# STM32MP25_CM0P register map
File version: 1.0
CPU: CM0PLUS r0p1, little endian, MPU, no FPU, vendor SysTick, 8 interrupt priority bits
Registers are 32-bit, read-write, reset 0x0 unless marked. A register's access mark holds for its fields unless they carry their own. Offsets are from the block's base; [hi:lo] are bit positions.

## IWDG5 — IWDG register block
Base 0x46090000
0x00 IWDG_KR wo — IWDG key register
  [15:0] KEY — Key value (write only, read 0x0000) These bits must be written by software at regular intervals with the key value 0xAAAA, otherwise the watchdog generates a reset when the counter reaches 0. Writing the key value 0x5555 to enable access to the IWDG_PR, IWDG_RLR and IWDG_WINR registers (see ) Writing the key value 0xCCCC starts the watchdog (except if the hardware watchdog option is selected)
0x04 IWDG_PR reset 0xF — IWDG prescaler register
  [3:0] PR — Prescaler divider These bits are write access protected see . They are written by software to select the prescaler divider feeding the counter clock. PVU bit of the must be reset in order to be able to change the prescaler divider. others: divider / 1024 Note: Reading this register returns the prescaler value from the VDD voltage domain. This value may not be up to date/valid if a write operation to this register is ongoing. For this reason the value read from this register is valid only when the PVU bit in the status register (IWDG_SR) is reset.
    0=divider / 4; 1=divider / 8; 2=divider / 16; 3=divider / 32; 4=divider / 64; 5=divider / 128; 6=divider / 256; 7=divider / 512
0x08 IWDG_RLR reset 0xFFF — IWDG reload register
  [11:0] RL — Watchdog counter reload value These bits are write access protected see . They are written by software to define the value to be loaded in the watchdog counter each time the value 0xAAAA is written in the . The watchdog counter counts down from this value. The timeout period is a function of this value and the prescaler.clock. It is not recommended to set RL[11:0] to a value lower than 2. The RVU bit in the must be reset to be able to change the reload value. Note: Reading this register returns the reload value from the VDD voltage domain. This value may not be up to date/valid if a write operation to this register is ongoing on it. For this reason the value read from this register is valid only when the RVU bit in the status register (IWDG_SR) is reset.
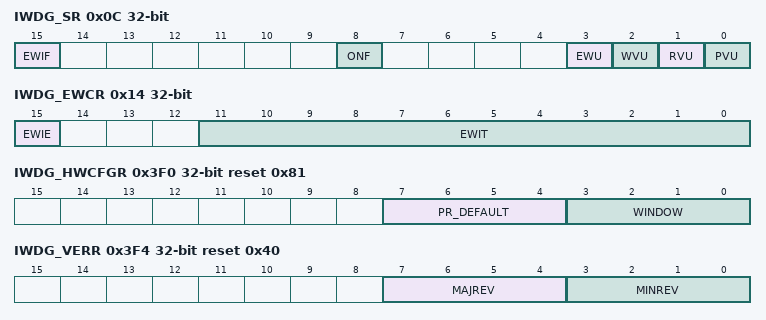
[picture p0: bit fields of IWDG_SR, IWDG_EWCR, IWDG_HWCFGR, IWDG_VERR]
0x0C IWDG_SR ro — IWDG status register
  [15] EWIF — Watchdog Early interrupt flag This bit is set to 1 by hardware in order to indicate that an early interrupt is pending. This bit must be cleared by the software by writing the bit EWIC of (IWDG_ICR) to 1 .
  [8] ONF — Watchdog enable status bit Set to 1 by hardware as soon as the IWDG is started, remains to 1 until the IWDG is reset.
    0=The IWDG is not activated; 1=The IWDG is activated and needs to be refreshed regularly by the application
  [3] EWU — Watchdog interrupt comparator value update This bit is set by hardware to indicate that an update of the interrupt comparator value (EWIT[11:0]) or an update of the EWIE is ongoing. It is reset by hardware when the update operation is completed in the VDD voltage domain (takes up to three periods of the IWDG kernel clock iwdg_ker_ck). The EWIT[11:0] and EWIE fields can be updated only when EWU bit is reset.
  [2] WVU — Watchdog counter window value update This bit is set by hardware to indicate that an update of the window value is ongoing. It is reset by hardware when the reload value update operation is completed in the VDD voltage domain (takes up to 3 periods of the IWDG kernel clock iwdg_ker_ck). The window value can be updated only when WVU bit is reset. This bit is generated only if generic 'window'= 1
  [1] RVU — Watchdog counter reload value update This bit is set by hardware to indicate that an update of the reload value is ongoing. It is reset by hardware when the reload value update operation is completed in the VDD voltage domain (takes up to 3 periods of the IWDG kernel clock iwdg_ker_ck). The reload value can be updated only when RVU bit is reset.
  [0] PVU — Watchdog prescaler value update This bit is set by hardware to indicate that an update of the prescaler value is ongoing. It is reset by hardware when the prescaler update operation is completed in the VDD voltage domain (takes up to 3 periods of the IWDG kernel clock iwdg_ker_ck). The prescaler value can be updated only when PVU bit is reset.
0x10 IWDG_WINR reset 0xFFF — IWDG window register
  [11:0] WIN — Watchdog counter window value These bits are write access protected, see , they contain the high limit of the window value to be compared with the downcounter. To prevent a reset, the IWDCNT downcounter must be reloaded when its value is lower than WIN[11:0]+1 and greater than 1. The WVU bit in the must be reset to be able to change the reload value. Note: Reading this register returns the reload value from the VDD voltage domain. This value may not be valid if a write operation to this register is ongoing. For this reason the value read from this register is valid only when the WVU bit in the (IWDG_SR) is reset.
0x14 IWDG_EWCR — IWDG early wakeup interrupt register
  [15] EWIE — Watchdog early interrupt enable Set and reset by software. The EWU bit in the must be reset to be able to change the value of this bit.
    0=The early interrupt interface is disabled; 1=The early interrupt interface is enabled
  [11:0] EWIT — Watchdog counter window value These bits are write access protected, see . They are written by software to define at which position of the IWDCNT down-counter, the early wakeup interrupt must be generated. The early interrupt will be generated when the IWDCNT is lower or equal to EWIT[11:0] - 1. EWIT[11:0] must be bigger than 1 . An interrupt is generated only if EWIE = 1 . The EWU bit in the must be reset to be able to change the reload value. Note: Reading this register returns the Early wakeup comparator value and the Interrupt enable bit from the VDD voltage domain. This value may not be up to date/valid if a write operation to this register is ongoing, hence the value read from this register is valid only when the EWU bit in the is reset.
0x18 IWDG_ICR — IWDG interrupt clear register
  [15] EWIC — Watchdog early interrupt acknowledge The software must write a 1 into this bit to acknowledge the early wakeup interrupt and to clear the EWIF flag. Writing 0 has not effect, reading this flag will return a 0 .
0x3F0 IWDG_HWCFGR ro reset 0x81 — IWDG hardware configuration register
  [7:4] PR_DEFAULT — Prescaler default value This field gives the default value of the prescaler (see of prescaler register (IWDG_PR) Other combinations: Reserved
    0=Prescaler (PR[3:0]) default value after reset is 0000; 1=Prescaler (PR[3:0]) default value after reset is 0001; 2=Prescaler (PR[3:0]) default value after reset is 0010; 3=Prescaler (PR[3:0]) default value after reset is 0011; 4=Prescaler (PR[3:0]) default value after reset is 0100; 5=Prescaler (PR[3:0]) default value after reset is 0101; 6=Prescaler (PR[3:0]) default value after reset is 0110; 7=Prescaler (PR[3:0]) default value after reset is 0111; 8=Prescaler (PR[3:0]) default value after reset is 1000
  [3:0] WINDOW — Support of Window function Other combinations: Reserved
    0=Window option disabled; 1=Window option enabled
0x3F4 IWDG_VERR ro reset 0x40 — IWDG version register
  [7:4] MAJREV — Major revision These bits return the IWDG major revision.
  [3:0] MINREV — Minor revision These bits return the IWDG minor revision.
0x3F8 IWDG_IDR ro reset 0x120041 — IWDG identification register
  [31:0] ID — IWDG identifier These bits return the IWDG identifier value.
0x3FC IWDG_SIDR ro reset 0xA3C5DD01 — IWDG size identification register
  [31:0] SID — IWDG size identifier These bits return the size of the memory region allocated to IWDG registers. The address decoding range is 1 KByte.
